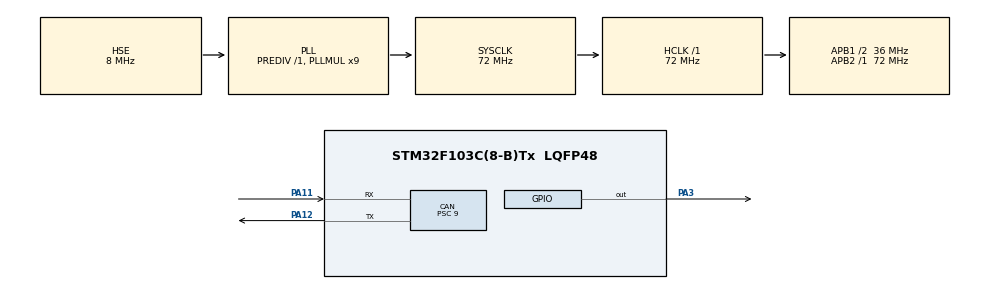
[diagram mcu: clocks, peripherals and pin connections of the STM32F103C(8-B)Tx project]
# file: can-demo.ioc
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CAN.BS1=CAN_BS1_3TQ
CAN.BS2=CAN_BS2_4TQ
CAN.CalculateBaudRate=500000
CAN.CalculateTimeBit=2000
CAN.CalculateTimeQuantum=250.0
CAN.Prescaler=9
Mcu.Family=STM32F1
Mcu.Name=STM32F103C(8-B)Tx
Mcu.Package=LQFP48
NVIC.PriorityGroup=NVIC_PRIORITYGROUP_4
NVIC.USB_LP_CAN1_RX0_IRQn=true\:0\:0\:false\:false\:true\:true\:true
PA11.Mode=CAN_Activate
PA11.Signal=CAN_RX
PA12.Mode=CAN_Activate
PA12.Signal=CAN_TX
PA13.Mode=Trace_Asynchronous_SW
PA13.Signal=SYS_JTMS-SWDIO
PA14.Mode=Trace_Asynchronous_SW
PA14.Signal=SYS_JTCK-SWCLK
PA3.Signal=GPIO_Output
PB3.Mode=Trace_Asynchronous_SW
PB3.Signal=SYS_JTDO-TRACESWO
PD0-OSC_IN.Mode=HSE-External-Oscillator
PD0-OSC_IN.Signal=RCC_OSC_IN
PD1-OSC_OUT.Mode=HSE-External-Oscillator
PD1-OSC_OUT.Signal=RCC_OSC_OUT
ProjectManager.HeapSize=0x200
ProjectManager.StackSize=0x400
ProjectManager.TargetToolchain=STM32CubeIDE
RCC.AHBFreq_Value=72000000
RCC.APB1CLKDivider=RCC_HCLK_DIV2
RCC.APB1Freq_Value=36000000
RCC.APB1TimFreq_Value=72000000
RCC.APB2Freq_Value=72000000
RCC.APB2TimFreq_Value=72000000
RCC.HCLKFreq_Value=72000000
RCC.PLLMUL=RCC_PLL_MUL9
RCC.PLLSourceVirtual=RCC_PLLSOURCE_HSE
RCC.SYSCLKFreq_VALUE=72000000
RCC.SYSCLKSource=RCC_SYSCLKSOURCE_PLLCLK
RCC.USBFreq_Value=72000000
board=custom

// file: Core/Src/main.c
/* USER CODE BEGIN Header */
/**
  ******************************************************************************
  * @file           : main.c
  * @brief          : Main program body
  ******************************************************************************
  * @attention
  *
  * Copyright (c) 2022 STMicroelectronics.
  * All rights reserved.
  *
  * This software is licensed under terms that can be found in the LICENSE file
  * in the root directory of this software component.
  * If no LICENSE file comes with this software, it is provided AS-IS.
  *
  ******************************************************************************
  */
/* USER CODE END Header */
#include "main.h"

CAN_HandleTypeDef hcan;

void SystemClock_Config(void);
static void MX_GPIO_Init(void);
static void MX_CAN_Init(void);

int main(void)
{

  /* MCU Configuration--------------------------------------------------------*/

  /* Reset of all peripherals, Initializes the Flash interface and the Systick. */
  HAL_Init();

  /* Configure the system clock */
  SystemClock_Config();

  /* Initialize all configured peripherals */
  MX_GPIO_Init();
  MX_CAN_Init();
  /* USER CODE BEGIN 2 */

  CAN_TxHeaderTypeDef txHeader;
  CAN_RxHeaderTypeDef rxHeader
  uint8_t canRX[8] = {0x00, 0x01, 0x02, 0x03, 0x04, 0x05, 0x06, 0x07};
  uint32_t pTxMailbox;
  HAL_StatusTypeDef mesgSend;
  // ************************** //
  // SETUP FILTERS FOR CAN HERE
  // hal_can_configFilter()
	CAN_FilterTypeDef filter1; // setup a filter for each message we're looking for
	filter1.FilterBank = 0;
  filter1.FilterIdHigh = 0;
	filter1.FilterIdLow = 0;
	filter1.FilterMaskIdHigh = 0;
	filter1.FilterMaskIdLow = 0;
	filter1.FilterFIFOAssignment = CAN_FILTER_FIFO0;
	filter1.FilterMode = CAN_FILTERMODE_IDMASK;
	filter1.FilterScale = CAN_FILTERSCALE_32BIT;
	filter1.FilterActivation = ENABLE;
  FILTER1.SlaveStartFilterBank = 14;

  HAL_CAN_ConfigFilter(&hcan,&filter1); //Initialize CAN Filter
  HAL_CAN_Start(&hcan); //Initialize CAN Bus
  HAL_CAN_ActivateNotification(&hcan,CAN_IT_RX_FIFO0_MSG_PENDING);// Initialize CAN Bus Rx Interrupt

  txHeader.DLC = 8; // Number of bites to be transmitted max- 8
  txHeader.IDE = CAN_ID_STD;
  txHeader.RTR = CAN_RTR_DATA;
  txHeader.StdId = 0x030;
  txHeader.ExtId = 0x02;
  txHeader.TransmitGlobalTime = DISABLE;

  // Also use Hal_can_start() to start the service
  HAL_StatusTypeDef can_status;

  // ************************** //

  /* USER CODE END 2 */

  /* Infinite loop */
  /* USER CODE BEGIN WHILE */
  while (1)
  {

    // send a message
    uint8_t csend[] = {0x01,0x02,0x03,0x04,0x05,0x06,0x07,0x08}; // Tx Buffer
    HAL_CAN_AddTxMessage(&hcan,&txHeader,csend,&canMailbox); // Send Message

    // Check for messages
    // do something?

    HAL_Delay(500);

    /* USER CODE END WHILE */

  }
}

void HAL_CAN_RxFifo0MsgPendingCallback(CAN_HandleTypeDef *hcan1)
{
	HAL_CAN_GetRxMessage(hcan1, CAN_RX_FIFO0, &rxHeader, canRX); //Receive CAN bus message to canRX buffer
	HAL_GPIO_TogglePin(GPIOC, GPIO_PIN_13);// toggle PA3 LED

}

void SystemClock_Config(void)
{
  RCC_OscInitTypeDef RCC_OscInitStruct = {0};
  RCC_ClkInitTypeDef RCC_ClkInitStruct = {0};

  /** Initializes the RCC Oscillators according to the specified parameters
  * in the RCC_OscInitTypeDef structure.
  */
  RCC_OscInitStruct.OscillatorType = RCC_OSCILLATORTYPE_HSE;
  RCC_OscInitStruct.HSEState = RCC_HSE_ON;
  RCC_OscInitStruct.HSEPredivValue = RCC_HSE_PREDIV_DIV1;
  RCC_OscInitStruct.HSIState = RCC_HSI_ON;
  RCC_OscInitStruct.PLL.PLLState = RCC_PLL_ON;
  RCC_OscInitStruct.PLL.PLLSource = RCC_PLLSOURCE_HSE;
  RCC_OscInitStruct.PLL.PLLMUL = RCC_PLL_MUL9;
  if (HAL_RCC_OscConfig(&RCC_OscInitStruct) != HAL_OK)
  {
    Error_Handler();
  }
  /** Initializes the CPU, AHB and APB buses clocks
  */
  RCC_ClkInitStruct.ClockType = RCC_CLOCKTYPE_HCLK|RCC_CLOCKTYPE_SYSCLK
                              |RCC_CLOCKTYPE_PCLK1|RCC_CLOCKTYPE_PCLK2;
  RCC_ClkInitStruct.SYSCLKSource = RCC_SYSCLKSOURCE_PLLCLK;
  RCC_ClkInitStruct.AHBCLKDivider = RCC_SYSCLK_DIV1;
  RCC_ClkInitStruct.APB1CLKDivider = RCC_HCLK_DIV2;
  RCC_ClkInitStruct.APB2CLKDivider = RCC_HCLK_DIV1;

  if (HAL_RCC_ClockConfig(&RCC_ClkInitStruct, FLASH_LATENCY_2) != HAL_OK)
  {
    Error_Handler();
  }
}

static void MX_CAN_Init(void)
{

  hcan.Instance = CAN1;
  hcan.Init.Prescaler = 4;
  hcan.Init.Mode = CAN_MODE_NORMAL;
  hcan.Init.SyncJumpWidth = CAN_SJW_1TQ;
  hcan.Init.TimeSeg1 = CAN_BS1_13TQ;
  hcan.Init.TimeSeg2 = CAN_BS2_4TQ;
  hcan.Init.TimeTriggeredMode = DISABLE;
  hcan.Init.AutoBusOff = DISABLE;
  hcan.Init.AutoWakeUp = DISABLE;
  hcan.Init.AutoRetransmission = DISABLE;
  hcan.Init.ReceiveFifoLocked = DISABLE;
  hcan.Init.TransmitFifoPriority = DISABLE;
  if (HAL_CAN_Init(&hcan) != HAL_OK)
  {
    Error_Handler();
  }

}

static void MX_GPIO_Init(void)
{
  GPIO_InitTypeDef GPIO_InitStruct = {0};

  /* GPIO Ports Clock Enable */
  __HAL_RCC_GPIOC_CLK_ENABLE();
  __HAL_RCC_GPIOD_CLK_ENABLE();
  __HAL_RCC_GPIOA_CLK_ENABLE();
  __HAL_RCC_GPIOB_CLK_ENABLE();

  /*Configure GPIO pin Output Level */
  HAL_GPIO_WritePin(GPIOC, GPIO_PIN_13, GPIO_PIN_RESET);

  /*Configure GPIO pin : PC13 */
  GPIO_InitStruct.Pin = GPIO_PIN_13;
  GPIO_InitStruct.Mode = GPIO_MODE_OUTPUT_PP;
  GPIO_InitStruct.Pull = GPIO_NOPULL;
  GPIO_InitStruct.Speed = GPIO_SPEED_FREQ_LOW;
  HAL_GPIO_Init(GPIOC, &GPIO_InitStruct);

}

void Error_Handler(void)
{
  __disable_irq();
  while (1)
  {
  }
}
